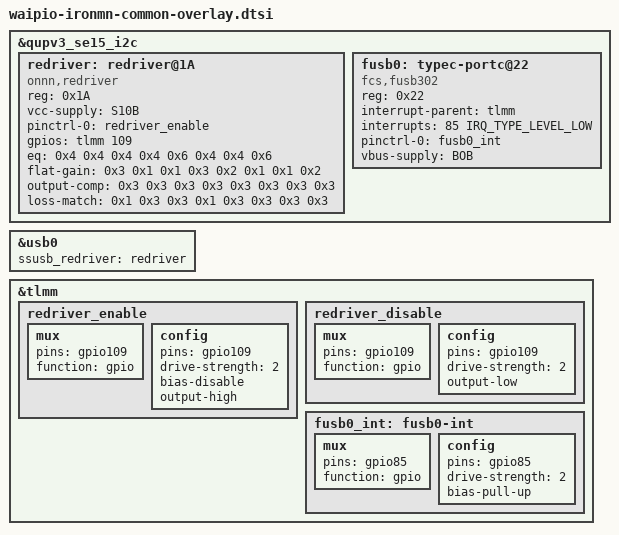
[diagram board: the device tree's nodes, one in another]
/* Copyright (c) 2021, The Linux Foundation. All rights reserved.
 *
 * This program is free software; you can redistribute it and/or modify
 * it under the terms of the GNU General Public License version 2 and
 * only version 2 as published by the Free Software Foundation.
 *
 * This program is distributed in the hope that it will be useful,
 * but WITHOUT ANY WARRANTY; without even the implied warranty of
 * MERCHANTABILITY or FITNESS FOR A PARTICULAR PURPOSE.  See the
 * GNU General Public License for more details.
 */

/*
   This base is original from "waipio-mtp-pm8008-overlay.dts"
*/
#include "waipio-moto-common-overlay-base.dtsi"
#include "waipio-moto-common-overlay.dtsi"

&qupv3_se15_i2c {
	status = "ok";

	redriver: redriver@1A {
		compatible = "onnn,redriver";
		reg = <0x1A>;
		vcc-supply = <&S10B>;
		pinctrl-names = "default";
		pinctrl-0 = <&redriver_enable>;

		gpios = <&tlmm 109 0>;

		eq = /bits/ 8 <
			/* Parameters for USB */
			0x4 0x4 0x4 0x4
			/* Parameters for DP */
			0x6 0x4 0x4 0x6>;
		flat-gain = /bits/ 8 <
			/* Parameters for USB */
			0x3 0x1 0x1 0x3
			/* Parameters for DP */
			0x2 0x1 0x1 0x2>;
		output-comp = /bits/ 8 <
			/* Parameters for USB */
			0x3 0x3 0x3 0x3
			/* Parameters for DP */
			0x3 0x3 0x3 0x3>;
		loss-match = /bits/ 8 <
			/* Parameters for USB */
			0x1 0x3 0x3 0x1
			/* Parameters for DP */
			0x3 0x3 0x3 0x3>;
	};

	fusb0: typec-portc@22 {
		compatible = "fcs,fusb302";
		reg = <0x22>;
		interrupt-parent = <&tlmm>;
		interrupts = <85 IRQ_TYPE_LEVEL_LOW>;
		pinctrl-names = "default";
		pinctrl-0 = <&fusb0_int>;
		vbus-supply = <&BOB>;
		status = "okay";
	};
};

&usb0 {
	ssusb_redriver = <&redriver>;
};

&redriver {
	status = "ok";
};

&tlmm {
	redriver_enable: redriver_enable {
		mux {
			pins = "gpio109";
			function = "gpio";
		};

		config {
			pins = "gpio109";
			drive-strength = <2>;
			bias-disable; /* NO PULL */
			output-high;
		};
	};

	redriver_disable: redriver_disable {
		mux {
			pins = "gpio109";
			function = "gpio";
		};

		config {
			pins = "gpio109";
			drive-strength = <2>;
			output-low;
		};
	};

	fusb0_int: fusb0-int {
		mux {
			pins = "gpio85";
			function = "gpio";
		};

		config {
			pins = "gpio85";
			drive-strength = <2>;
			bias-pull-up;
		};
	};
};
